# NUC029AN_v1 register map
File version: 1.0
Registers are 32-bit, read-write, reset 0x0 unless marked. A register's access mark holds for its fields unless they carry their own. Offsets are from the block's base; [hi:lo] are bit positions; {n}, {i} and the like mark numbered series.

## INT — INT Register Map
Base 0x50000300
0x00 IRQ0_SRC ro reset not defined — IRQ0 (BOD) interrupt source identity
  [2:0] INT_SRC — Bit0 : BOD_INT
0x04 IRQ1_SRC ro reset not defined — IRQ1 (WDT) interrupt source identity
  [2:0] INT_SRC — Bit0 : WDT_INT
0x08 IRQ2_SRC ro reset not defined — IRQ2 (EINT0) interrupt source identity
  [2:0] INT_SRC — Bit0: EINT0 - external interrupt 0 from P3.2
0x0C IRQ3_SRC ro reset not defined — IRQ3 (EINT1) interrupt source identity
  [2:0] INT_SRC — Bit0: EINT1 - external interrupt 1 from P3.3
0x10 IRQ4_SRC ro reset not defined — IRQ4 (P0/1) interrupt source identity
  [2:0] INT_SRC — Bit1: P1_INT. Bit0: P0_INT
0x14 IRQ5_SRC ro reset not defined — IRQ5 (P2/3/4) interrupt source identity
  [2:0] INT_SRC — Bit2: P4_INT. Bit1: P3_INT. Bit0: P2_INT
0x18 IRQ6_SRC ro reset not defined — IRQ6 (PWMA) interrupt source identity
  [3:0] INT_SRC — Bit3: PWM3_INT. Bit2: PWM2_INT. Bit1: PWM1_INT. Bit0: PWM0_INT
0x1C IRQ7_SRC ro reset not defined — IRQ7 (PWMB) interrupt source identity
  [3:0] INT_SRC — Bit3: PWM7_INT. Bit2: PWM6_INT. Bit1: PWM5_INT. Bit0: PWM4_INT
{0x0+4i} IRQ{i}_SRC ro reset not defined (i=8..11) — IRQ{i} (TMR{i-8}) interrupt source identity
  [2:0] INT_SRC — Bit0: TMR{i-8}_INT
0x30 IRQ12_SRC ro reset not defined — IRQ12 (UART0) interrupt source identity
  [2:0] INT_SRC — Bit0: UART0_INT
0x34 IRQ13_SRC ro reset not defined — IRQ13 (UART1) interrupt source identity
  [2:0] INT_SRC — Bit0: UART1_INT
0x38 IRQ14_SRC ro reset not defined — IRQ14 (SPI0) interrupt source identity
  [2:0] INT_SRC — Bit0: SPI0_INT
0x3C IRQ15_SRC ro reset not defined — IRQ15 (SPI1) interrupt source identity
  [2:0] INT_SRC — Bit0: SPI1_INT
0x40 IRQ16_SRC ro reset not defined — Reserved
0x44 IRQ17_SRC ro reset not defined — Reserved
0x48 IRQ18_SRC ro reset not defined — IRQ18 (I2C0) interrupt source identity
  [2:0] INT_SRC — Bit0: I2C0_INT
0x4C IRQ19_SRC ro reset not defined — IRQ19 (I2C1) interrupt source identity
  [2:0] INT_SRC — Bit0: I2C1_INT
{0x0+4i} IRQ{i}_SRC ro reset not defined (i=20..24) — Reserved
0x64 IRQ25_SRC ro reset not defined — IRQ25 (ACMPA) interrupt source identity
  [2:0] INT_SRC — Bit0: ACMPA_INT
0x68 IRQ26_SRC ro reset not defined — IRQ26 (ACMPB) interrupt source identity
  [2:0] INT_SRC — Bit0: ACMPB_INT
0x6C IRQ27_SRC ro reset not defined — Reserved
0x70 IRQ28_SRC ro reset not defined — IRQ28 (PWRWU) interrupt source identity
  [2:0] INT_SRC — Bit0: PWRWU_INT
0x74 IRQ29_SRC ro reset not defined — IRQ29 (ADC) interrupt source identity
  [2:0] INT_SRC — Bit0: ADC_INT
0x78 IRQ30_SRC ro reset not defined — Reserved
0x7C IRQ31_SRC ro reset not defined — Reserved
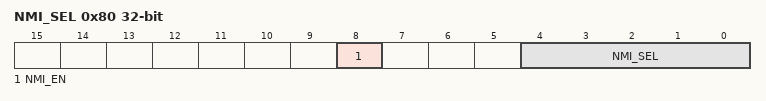
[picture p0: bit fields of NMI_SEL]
0x80 NMI_SEL — NMI source interrupt select control register
  [8] NMI_EN — NMI interrupt enable (write-protection bit). This bit is the protected bit. It means programming this needs to write "59h", "16h", "88h" to address 0x5000_0100 to disable register protection. Reference the register REGWRPROT at address GCR_BA+0x100
    0=Disable NMI interrupt; 1=Enable NMI interrupt
  [4:0] NMI_SEL — NMI interrupt source selection. The NMI interrupt to Cortex-M0 can be selected from one of the interrupt[31:0]. The NMI_SEL bit[4:0] used to select the NMI interrupt source
0x84 MCU_IRQ — MCU Interrupt Request Source Register
  [31:0] MCU_IRQ — MCU IRQ Source Register. The MCU_IRQ collects all the interrupts from the peripherals and generates the synchronous interrupt to Cortex-M0 core. There are two modes to generate interrupt to Cortex-M0, the normal mode and test mode. The MCU_IRQ collects all interrupts from each peripheral and synchronizes them then interrupts the Cortex-M0. When the MCU_IRQ[n] is "0", set MCU_IRQ[n] "1" will generate an interrupt to Cortex_M0 NVIC[n]. When the MCU_IRQ[n] is "1" (mean an interrupt is assert), set 1 to the MCU_IRQ[n] will clear the interrupt and set MCU_IRQ[n] "0" : no any effect
